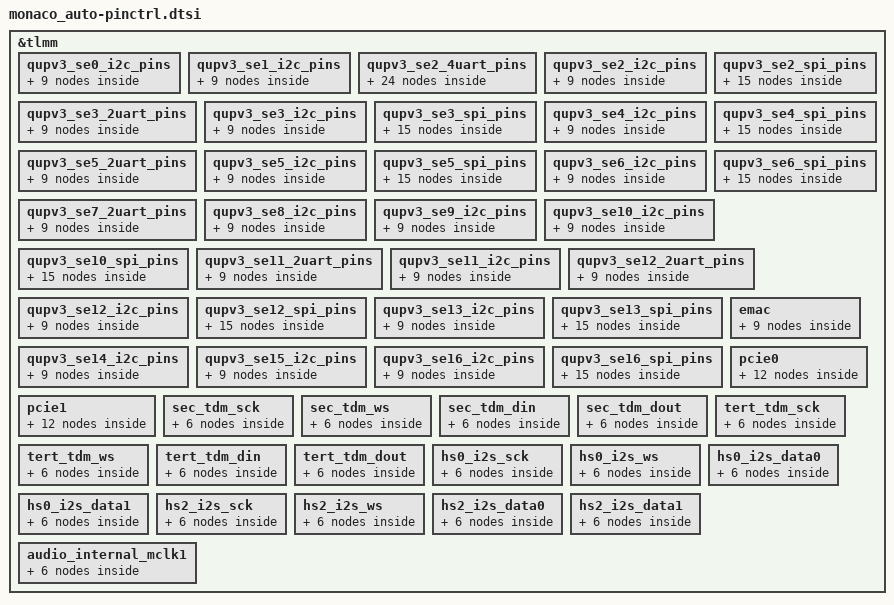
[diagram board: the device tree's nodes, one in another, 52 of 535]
&tlmm {
	qupv3_se0_i2c_pins: qupv3_se0_i2c_pins {
		qupv3_se0_i2c_sda_active: qupv3_se0_i2c_sda_active {
			mux {
				pins = "gpio17";
				function = "qup0_se0_l0";
			};

			config {
				pins = "gpio17";
				drive-strength = <2>;
				bias-pull-up;
			};
		};

		qupv3_se0_i2c_scl_active: qupv3_se0_i2c_scl_active {
			mux {
				pins = "gpio18";
				function = "qup0_se0_l1";
			};

			config {
				pins = "gpio18";
				drive-strength = <2>;
				bias-pull-up;
			};
		};

		qupv3_se0_i2c_sleep: qupv3_se0_i2c_sleep {
			mux {
				pins = "gpio17", "gpio18";
				function = "gpio";
			};

			config {
				pins = "gpio17", "gpio18";
				drive-strength = <2>;
				bias-disable;
			};
		};
	};

	qupv3_se1_i2c_pins: qupv3_se1_i2c_pins {
		qupv3_se1_i2c_sda_active: qupv3_se1_i2c_sda_active {
			mux {
				pins = "gpio19";
				function = "qup0_se1_l0";
			};

			config {
				pins = "gpio19";
				drive-strength = <2>;
				bias-pull-up;
			};
		};

		qupv3_se1_i2c_scl_active: qupv3_se1_i2c_scl_active {
			mux {
				pins = "gpio20";
				function = "qup0_se1_l1";
			};

			config {
				pins = "gpio20";
				drive-strength = <2>;
				bias-pull-up;
			};
		};

		qupv3_se1_i2c_sleep: qupv3_se1_i2c_sleep {
			mux {
				pins = "gpio19", "gpio20";
				function = "gpio";
			};

			config {
				pins = "gpio19", "gpio20";
				drive-strength = <2>;
				bias-disable;
			};
		};
	};

	qupv3_se2_4uart_pins: qupv3_se2_4uart_pins {
		qupv3_se2_default_cts: qupv3_se2_default_cts {
			mux {
				pins = "gpio33";
				function = "gpio";
			};

			config {
				pins = "gpio33";
				drive-strength = <2>;
				bias-disable;
			};
		};

		qupv3_se2_default_rts: qupv3_se2_default_rts {
			mux {
				pins = "gpio34";
				function = "gpio";
			};

			config {
				pins = "gpio34";
				drive-strength = <2>;
				bias-pull-down;
			};
		};

		qupv3_se2_default_tx: qupv3_se2_default_tx {
			mux {
				pins = "gpio35";
				function = "gpio";
			};

			config {
				pins = "gpio35";
				drive-strength = <2>;
				bias-pull-up;
			};
		};

		qupv3_se2_default_rx: qupv3_se2_default_rx {
			mux {
				pins = "gpio36";
				function = "gpio";
			};

			config {
				pins = "gpio36";
				drive-strength = <2>;
				bias-pull-down;
			};
		};

		qupv3_se2_cts: qupv3_se2_cts {
			mux {
				pins = "gpio33";
				function = "qup0_se2_l0";
			};

			config {
				pins = "gpio33";
				drive-strength = <2>;
				bias-disable;
			};
		};

		qupv3_se2_rts: qupv3_se2_rts {
			mux {
				pins = "gpio34";
				function = "qup0_se2_l1";
			};

			config {
				pins = "gpio34";
				drive-strength = <2>;
				bias-pull-down;
			};
		};

		qupv3_se2_tx: qupv3_se2_tx {
			mux {
				pins = "gpio35";
				function = "qup0_se2_l2";
			};

			config {
				pins = "gpio35";
				drive-strength = <2>;
				bias-pull-up;
			};
		};

		qupv3_se2_rx: qupv3_se2_rx {
			mux {
				pins = "gpio36";
				function = "qup0_se2_l3";
			};

			config {
				pins = "gpio36";
				drive-strength = <2>;
				bias-disable;
			};
		};
	};

	qupv3_se2_i2c_pins: qupv3_se2_i2c_pins {
		qupv3_se2_i2c_sda_active: qupv3_se2_i2c_sda_active {
			mux {
				pins = "gpio33";
				function = "qup0_se2_l0";
			};

			config {
				pins = "gpio33";
				drive-strength = <2>;
				bias-pull-up;
			};
		};

		qupv3_se2_i2c_scl_active: qupv3_se2_i2c_scl_active {
			mux {
				pins = "gpio34";
				function = "qup0_se2_l1";
			};

			config {
				pins = "gpio34";
				drive-strength = <2>;
				bias-pull-up;
			};
		};

		qupv3_se2_i2c_sleep: qupv3_se2_i2c_sleep {
			mux {
				pins = "gpio33", "gpio34";
				function = "gpio";
			};

			config {
				pins = "gpio33", "gpio34";
				drive-strength = <2>;
				bias-disable;
			};
		};
	};

	qupv3_se2_spi_pins: qupv3_se2_spi_pins {
		qupv3_se2_spi_miso_active: qupv3_se2_spi_miso_active {
			mux {
				pins = "gpio33";
				function = "qup0_se2_l0";
			};

			config {
				pins = "gpio33";
				drive-strength = <6>;
				bias-disable;
			};
		};

		qupv3_se2_spi_mosi_active: qupv3_se2_spi_mosi_active {
			mux {
				pins = "gpio34";
				function = "qup0_se2_l1";
			};

			config {
				pins = "gpio34";
				drive-strength = <6>;
				bias-disable;
			};
		};

		qupv3_se2_spi_clk_active: qupv3_se2_spi_clk_active {
			mux {
				pins = "gpio35";
				function = "qup0_se2_l2";
			};

			config {
				pins = "gpio35";
				drive-strength = <6>;
				bias-disable;
			};
		};

		qupv3_se2_spi_cs_active: qupv3_se2_spi_cs_active {
			mux {
				pins = "gpio36";
				function = "qup0_se2_l3";
			};

			config {
				pins = "gpio36";
				drive-strength = <6>;
				bias-disable;
			};
		};

		qupv3_se2_spi_sleep: qupv3_se2_spi_sleep {
			mux {
				pins = "gpio33", "gpio34",
					"gpio35", "gpio36";
				function = "gpio";
			};

			config {
				pins = "gpio33", "gpio34",
					"gpio35", "gpio36";
				drive-strength = <2>;
				bias-disable;
			};
		};
	};

	qupv3_se3_2uart_pins: qupv3_se3_2uart_pins {
		qupv3_se3_2uart_tx_active: qupv3_se3_2uart_tx_active {
			mux {
				pins = "gpio27";
				function = "qup0_se3_l2";
			};

			config {
				pins = "gpio27";
				drive-strength = <2>;
				bias-disable;
			};
		};

		qupv3_se3_2uart_rx_active: qupv3_se3_2uart_rx_active {
			mux {
				pins = "gpio28";
				function = "qup0_se3_l3";
			};

			config {
				pins = "gpio28";
				drive-strength = <2>;
				bias-disable;
			};
		};

		qupv3_se3_2uart_sleep: qupv3_se3_2uart_sleep {
			mux {
				pins = "gpio27", "gpio28";
				function = "gpio";
			};

			config {
				pins = "gpio27", "gpio28";
				drive-strength = <2>;
				bias-pull-down;
			};
		};
	};

	qupv3_se3_i2c_pins: qupv3_se3_i2c_pins {
		qupv3_se3_i2c_sda_active: qupv3_se3_i2c_sda_active {
			mux {
				pins = "gpio25";
				function = "qup0_se3_l0";
			};

			config {
				pins = "gpio25";
				drive-strength = <2>;
				bias-pull-up;
			};
		};

		qupv3_se3_i2c_scl_active: qupv3_se3_i2c_scl_active {
			mux {
				pins = "gpio26";
				function = "qup0_se3_l1";
			};

			config {
				pins = "gpio26";
				drive-strength = <2>;
				bias-pull-up;
			};
		};

		qupv3_se3_i2c_sleep: qupv3_se3_i2c_sleep {
			mux {
				pins = "gpio25", "gpio26";
				function = "gpio";
			};

			config {
				pins = "gpio25", "gpio26";
				drive-strength = <2>;
				bias-disable;
			};
		};
	};

	qupv3_se3_spi_pins: qupv3_se3_spi_pins {
		qupv3_se3_spi_miso_active: qupv3_se3_spi_miso_active {
			mux {
				pins = "gpio25";
				function = "qup0_se3_l0";
			};

			config {
				pins = "gpio25";
				drive-strength = <6>;
				bias-disable;
			};
		};

		qupv3_se3_spi_mosi_active: qupv3_se3_spi_mosi_active {
			mux {
				pins = "gpio26";
				function = "qup0_se3_l1";
			};

			config {
				pins = "gpio26";
				drive-strength = <6>;
				bias-disable;
			};
		};

		qupv3_se3_spi_clk_active: qupv3_se3_spi_clk_active {
			mux {
				pins = "gpio27";
				function = "qup0_se3_l2";
			};

			config {
				pins = "gpio27";
				drive-strength = <6>;
				bias-disable;
			};
		};

		qupv3_se3_spi_cs_active: qupv3_se3_spi_cs_active {
			mux {
				pins = "gpio28";
				function = "qup0_se3_l3";
			};

			config {
				pins = "gpio28";
				drive-strength = <6>;
				bias-disable;
			};
		};

		qupv3_se3_spi_sleep: qupv3_se3_spi_sleep {
			mux {
				pins = "gpio25", "gpio26",
					"gpio27", "gpio28";
				function = "gpio";
			};

			config {
				pins = "gpio25", "gpio26",
					"gpio27", "gpio28";
				drive-strength = <2>;
				bias-disable;
			};
		};
	};

	qupv3_se4_i2c_pins: qupv3_se4_i2c_pins {
		qupv3_se4_i2c_sda_active: qupv3_se4_i2c_sda_active {
			mux {
				pins = "gpio29";
				function = "qup0_se4_l0";
			};

			config {
				pins = "gpio29";
				drive-strength = <2>;
				bias-pull-up;
			};
		};

		qupv3_se4_i2c_scl_active: qupv3_se4_i2c_scl_active {
			mux {
				pins = "gpio30";
				function = "qup0_se4_l1";
			};

			config {
				pins = "gpio30";
				drive-strength = <2>;
				bias-pull-up;
			};
		};

		qupv3_se4_i2c_sleep: qupv3_se4_i2c_sleep {
			mux {
				pins = "gpio29", "gpio30";
				function = "gpio";
			};

			config {
				pins = "gpio29", "gpio30";
				drive-strength = <2>;
				bias-disable;
			};
		};
	};

	qupv3_se4_spi_pins: qupv3_se4_spi_pins {
		qupv3_se4_spi_miso_active: qupv3_se4_spi_miso_active {
			mux {
				pins = "gpio29";
				function = "qup0_se4_l0";
			};

			config {
				pins = "gpio29";
				drive-strength = <6>;
				bias-disable;
			};
		};

		qupv3_se4_spi_mosi_active: qupv3_se4_spi_mosi_active {
			mux {
				pins = "gpio30";
				function = "qup0_se4_l1";
			};

			config {
				pins = "gpio30";
				drive-strength = <6>;
				bias-disable;
			};
		};

		qupv3_se4_spi_clk_active: qupv3_se4_spi_clk_active {
			mux {
				pins = "gpio31";
				function = "qup0_se4_l2";
			};

			config {
				pins = "gpio31";
				drive-strength = <6>;
				bias-disable;
			};
		};

		qupv3_se4_spi_cs_active: qupv3_se4_spi_cs_active {
			mux {
				pins = "gpio32";
				function = "qup0_se4_l3";
			};

			config {
				pins = "gpio32";
				drive-strength = <6>;
				bias-disable;
			};
		};

		qupv3_se4_spi_sleep: qupv3_se4_spi_sleep {
			mux {
				pins = "gpio29", "gpio30",
					"gpio31", "gpio32";
				function = "gpio";
			};

			config {
				pins = "gpio29", "gpio30",
					"gpio31", "gpio32";
				drive-strength = <2>;
				bias-disable;
			};
		};
	};

	qupv3_se5_2uart_pins: qupv3_se5_2uart_pins {
		qupv3_se5_2uart_tx_active: qupv3_se5_2uart_tx_active {
			mux {
				pins = "gpio23";
				function = "qup0_se5_l2";
			};

			config {
				pins = "gpio23";
				drive-strength = <2>;
				bias-disable;
			};
		};

		qupv3_se5_2uart_rx_active: qupv3_se5_2uart_rx_active {
			mux {
				pins = "gpio24";
				function = "qup0_se5_l3";
			};

			config {
				pins = "gpio24";
				drive-strength = <2>;
				bias-disable;
			};
		};

		qupv3_se5_2uart_sleep: qupv3_se5_2uart_sleep {
			mux {
				pins = "gpio23", "gpio24";
				function = "gpio";
			};

			config {
				pins = "gpio23", "gpio24";
				drive-strength = <2>;
				bias-pull-down;
			};
		};
	};

	qupv3_se5_i2c_pins: qupv3_se5_i2c_pins {
		qupv3_se5_i2c_sda_active: qupv3_se5_i2c_sda_active {
			mux {
				pins = "gpio21";
				function = "qup0_se5_l0";
			};

			config {
				pins = "gpio21";
				drive-strength = <2>;
				bias-pull-up;
			};
		};

		qupv3_se5_i2c_scl_active: qupv3_se5_i2c_scl_active {
			mux {
				pins = "gpio22";
				function = "qup0_se5_l1";
			};

			config {
				pins = "gpio22";
				drive-strength = <2>;
				bias-pull-up;
			};
		};

		qupv3_se5_i2c_sleep: qupv3_se5_i2c_sleep {
			mux {
				pins = "gpio21", "gpio22";
				function = "gpio";
			};

			config {
				pins = "gpio21", "gpio22";
				drive-strength = <2>;
				bias-disable;
			};
		};
	};

	qupv3_se5_spi_pins: qupv3_se5_spi_pins {
		qupv3_se5_spi_miso_active: qupv3_se5_spi_miso_active {
			mux {
				pins = "gpio21";
				function = "qup0_se5_l0";
			};

			config {
				pins = "gpio21";
				drive-strength = <6>;
				bias-disable;
			};
		};

		qupv3_se5_spi_mosi_active: qupv3_se5_spi_mosi_active {
			mux {
				pins = "gpio22";
				function = "qup0_se5_l1";
			};

			config {
				pins = "gpio22";
				drive-strength = <6>;
				bias-disable;
			};
		};

		qupv3_se5_spi_clk_active: qupv3_se5_spi_clk_active {
			mux {
				pins = "gpio23";
				function = "qup0_se5_l2";
			};

			config {
				pins = "gpio23";
				drive-strength = <6>;
				bias-disable;
			};
		};

		qupv3_se5_spi_cs_active: qupv3_se5_spi_cs_active {
			mux {
				pins = "gpio24";
				function = "qup0_se5_l3";
			};

			config {
				pins = "gpio24";
				drive-strength = <6>;
				bias-disable;
			};
		};

		qupv3_se5_spi_sleep: qupv3_se5_spi_sleep {
			mux {
				pins = "gpio21", "gpio22",
					"gpio23", "gpio24";
				function = "gpio";
			};

			config {
				pins = "gpio21", "gpio22",
					"gpio23", "gpio24";
				drive-strength = <2>;
				bias-disable;
			};
		};
	};

	qupv3_se6_i2c_pins: qupv3_se6_i2c_pins {
		qupv3_se6_i2c_sda_active: qupv3_se6_i2c_sda_active {
			mux {
				pins = "gpio80";
				function = "qup0_se6_l0";
			};

			config {
				pins = "gpio80";
				drive-strength = <2>;
				bias-pull-up;
			};
		};

		qupv3_se6_i2c_scl_active: qupv3_se6_i2c_scl_active {
			mux {
				pins = "gpio81";
				function = "qup0_se6_l1";
			};

			config {
				pins = "gpio81";
				drive-strength = <2>;
				bias-pull-up;
			};
		};

		qupv3_se6_i2c_sleep: qupv3_se6_i2c_sleep {
			mux {
				pins = "gpio80", "gpio81";
				function = "gpio";
			};

			config {
				pins = "gpio80", "gpio81";
				drive-strength = <2>;
				bias-disable;
			};
		};
	};

	qupv3_se6_spi_pins: qupv3_se6_spi_pins {
		qupv3_se6_spi_miso_active: qupv3_se6_spi_miso_active {
			mux {
				pins = "gpio80";
				function = "qup0_se6_l0";
			};

			config {
				pins = "gpio80";
				drive-strength = <6>;
				bias-disable;
			};
		};

		qupv3_se6_spi_mosi_active: qupv3_se6_spi_mosi_active {
			mux {
				pins = "gpio81";
				function = "qup0_se6_l1";
			};

			config {
				pins = "gpio81";
				drive-strength = <6>;
				bias-disable;
			};
		};

		qupv3_se6_spi_clk_active: qupv3_se6_spi_clk_active {
			mux {
				pins = "gpio82";
				function = "qup0_se6_l2";
			};

			config {
				pins = "gpio82";
				drive-strength = <6>;
				bias-disable;
			};
		};

		qupv3_se6_spi_cs_active: qupv3_se6_spi_cs_active {
			mux {
				pins = "gpio83";
				function = "qup0_se6_l3";
			};

			config {
				pins = "gpio83";
				drive-strength = <6>;
				bias-disable;
			};
		};

		qupv3_se6_spi_sleep: qupv3_se6_spi_sleep {
			mux {
				pins = "gpio80", "gpio81",
					"gpio82", "gpio83";
				function = "gpio";
			};

			config {
				pins = "gpio80", "gpio81",
					"gpio82", "gpio83";
				drive-strength = <2>;
				bias-disable;
			};
		};
	};

	qupv3_se7_2uart_pins: qupv3_se7_2uart_pins {
		qupv3_se7_2uart_tx_active: qupv3_se7_2uart_tx_active {
			mux {
				pins = "gpio43";
				function = "qup0_se7_l2";
			};

			config {
				pins = "gpio43";
				drive-strength = <2>;
				bias-disable;
			};
		};

		qupv3_se7_2uart_rx_active: qupv3_se7_2uart_rx_active {
			mux {
				pins = "gpio44";
				function = "qup0_se7_l3";
			};

			config {
				pins = "gpio44";
				drive-strength = <2>;
				bias-disable;
			};
		};

		qupv3_se7_2uart_sleep: qupv3_se7_2uart_sleep {
			mux {
				pins = "gpio43", "gpio44";
				function = "gpio";
			};

			config {
				pins = "gpio43", "gpio44";
				drive-strength = <2>;
				bias-pull-down;
			};
		};
	};

	qupv3_se8_i2c_pins: qupv3_se8_i2c_pins {
		qupv3_se8_i2c_sda_active: qupv3_se8_i2c_sda_active {
			mux {
				pins = "gpio37";
				function = "qup1_se0_l0";
			};

			config {
				pins = "gpio37";
				drive-strength = <2>;
				bias-pull-up;
			};
		};

		qupv3_se8_i2c_scl_active: qupv3_se8_i2c_scl_active {
			mux {
				pins = "gpio38";
				function = "qup1_se0_l1";
			};

			config {
				pins = "gpio38";
				drive-strength = <2>;
				bias-pull-up;
			};
		};

		qupv3_se8_i2c_sleep: qupv3_se8_i2c_sleep {
			mux {
				pins = "gpio37", "gpio38";
				function = "gpio";
			};

			config {
				pins = "gpio37", "gpio38";
				drive-strength = <2>;
				bias-disable;
			};
		};
	};

	qupv3_se9_i2c_pins: qupv3_se9_i2c_pins {
		qupv3_se9_i2c_sda_active: qupv3_se9_i2c_sda_active {
			mux {
				pins = "gpio39";
				function = "qup1_se1_l0";
			};

			config {
				pins = "gpio39";
				drive-strength = <2>;
				bias-pull-up;
			};
		};

		qupv3_se9_i2c_scl_active: qupv3_se9_i2c_scl_active {
			mux {
				pins = "gpio40";
				function = "qup1_se1_l1";
			};

			config {
				pins = "gpio40";
				drive-strength = <2>;
				bias-pull-up;
			};
		};

		qupv3_se9_i2c_sleep: qupv3_se9_i2c_sleep {
			mux {
				pins = "gpio39", "gpio40";
				function = "gpio";
			};

			config {
				pins = "gpio39", "gpio40";
				drive-strength = <2>;
				bias-disable;
			};
		};
	};

	qupv3_se10_i2c_pins: qupv3_se10_i2c_pins {
		qupv3_se10_i2c_sda_active: qupv3_se10_i2c_sda_active {
			mux {
				pins = "gpio84";
				function = "qup1_se2_l0";
			};

			config {
				pins = "gpio84";
				drive-strength = <2>;
				bias-pull-up;
			};
		};

		qupv3_se10_i2c_scl_active: qupv3_se10_i2c_scl_active {
			mux {
				pins = "gpio85";
				function = "qup1_se2_l1";
			};

			config {
				pins = "gpio85";
				drive-strength = <2>;
				bias-pull-up;
			};
		};

		qupv3_se10_i2c_sleep: qupv3_se10_i2c_sleep {
			mux {
				pins = "gpio84", "gpio85";
				function = "gpio";
			};

			config {
				pins = "gpio84", "gpio85";
				drive-strength = <2>;
				bias-disable;
			};
		};
	};

	qupv3_se10_spi_pins: qupv3_se10_spi_pins {
		qupv3_se10_spi_miso_active: qupv3_se10_spi_miso_active {
			mux {
				pins = "gpio84";
				function = "qup1_se2_l0";
			};

			config {
				pins = "gpio84";
				drive-strength = <6>;
				bias-disable;
			};
		};

		qupv3_se10_spi_mosi_active: qupv3_se10_spi_mosi_active {
			mux {
				pins = "gpio85";
				function = "qup1_se2_l1";
			};

			config {
				pins = "gpio85";
				drive-strength = <6>;
				bias-disable;
			};
		};

		qupv3_se10_spi_clk_active: qupv3_se10_spi_clk_active {
			mux {
				pins = "gpio86";
				function = "qup1_se2_l2";
			};

			config {
				pins = "gpio86";
				drive-strength = <6>;
				bias-disable;
			};
		};

		qupv3_se10_spi_cs_active: qupv3_se10_spi_cs_active {
			mux {
				pins = "gpio87";
				function = "qup1_se2_l3";
			};

			config {
				pins = "gpio87";
				drive-strength = <6>;
				bias-disable;
			};
		};

		qupv3_se10_spi_sleep: qupv3_se10_spi_sleep {
			mux {
				pins = "gpio84", "gpio85",
					"gpio86", "gpio87";
				function = "gpio";
			};

			config {
				pins = "gpio84", "gpio85",
					"gpio86", "gpio87";
				drive-strength = <2>;
				bias-disable;
			};
		};
	};

	qupv3_se11_2uart_pins: qupv3_se11_2uart_pins {
		qupv3_se11_2uart_tx_active: qupv3_se11_2uart_tx_active {
			mux {
				pins = "gpio41";
				function = "qup1_se3_l2";
			};

			config {
				pins = "gpio41";
				drive-strength = <2>;
				bias-disable;
			};
		};

		qupv3_se11_2uart_rx_active: qupv3_se11_2uart_rx_active {
			mux {
				pins = "gpio42";
				function = "qup1_se3_l3";
			};

			config {
				pins = "gpio42";
				drive-strength = <2>;
				bias-disable;
			};
		};

		qupv3_se11_2uart_sleep: qupv3_se11_2uart_sleep {
			mux {
				pins = "gpio41", "gpio42";
				function = "gpio";
			};

			config {
				pins = "gpio41", "gpio42";
				drive-strength = <2>;
				bias-pull-down;
			};
		};
	};

	qupv3_se11_i2c_pins: qupv3_se11_i2c_pins {
		qupv3_se11_i2c_sda_active: qupv3_se11_i2c_sda_active {
			mux {
				pins = "gpio41";
				function = "qup1_se3_l0";
			};

			config {
				pins = "gpio41";
				drive-strength = <2>;
				bias-pull-up;
			};
		};

		qupv3_se11_i2c_scl_active: qupv3_se11_i2c_scl_active {
			mux {
				pins = "gpio42";
				function = "qup1_se3_l1";
			};

			config {
				pins = "gpio42";
				drive-strength = <2>;
				bias-pull-up;
			};
		};

		qupv3_se11_i2c_sleep: qupv3_se11_i2c_sleep {
			mux {
				pins = "gpio41", "gpio42";
				function = "gpio";
			};

			config {
				pins = "gpio41", "gpio42";
				drive-strength = <2>;
				bias-disable;
			};
		};
	};

	qupv3_se12_2uart_pins: qupv3_se12_2uart_pins {
		qupv3_se12_2uart_tx_active: qupv3_se12_2uart_tx_active {
			mux {
				pins = "gpio47";
				function = "qup1_se4_l2";
			};

			config {
				pins = "gpio47";
				drive-strength = <2>;
				bias-disable;
			};
		};

		qupv3_se12_2uart_rx_active: qupv3_se12_2uart_rx_active {
			mux {
				pins = "gpio48";
				function = "qup1_se4_l3";
			};

			config {
				pins = "gpio48";
				drive-strength = <2>;
				bias-disable;
			};
		};

		qupv3_se12_2uart_sleep: qupv3_se12_2uart_sleep {
			mux {
				pins = "gpio47", "gpio48";
				function = "gpio";
			};

			config {
				pins = "gpio47", "gpio48";
				drive-strength = <2>;
				bias-pull-down;
			};
		};
	};

	qupv3_se12_i2c_pins: qupv3_se12_i2c_pins {
		qupv3_se12_i2c_sda_active: qupv3_se12_i2c_sda_active {
			mux {
				pins = "gpio45";
				function = "qup1_se4_l0";
			};

			config {
				pins = "gpio45";
				drive-strength = <2>;
				bias-pull-up;
			};
		};

		qupv3_se12_i2c_scl_active: qupv3_se12_i2c_scl_active {
			mux {
				pins = "gpio46";
				function = "qup1_se4_l1";
			};

			config {
				pins = "gpio46";
				drive-strength = <2>;
				bias-pull-up;
			};
		};

		qupv3_se12_i2c_sleep: qupv3_se12_i2c_sleep {
			mux {
				pins = "gpio45", "gpio46";
				function = "gpio";
			};

			config {
				pins = "gpio45", "gpio46";
				drive-strength = <2>;
				bias-disable;
			};
		};
	};

	qupv3_se12_spi_pins: qupv3_se12_spi_pins {
		qupv3_se12_spi_miso_active: qupv3_se12_spi_miso_active {
			mux {
				pins = "gpio45";
				function = "qup1_se4_l0";
			};

			config {
				pins = "gpio45";
				drive-strength = <6>;
				bias-disable;
			};
		};

		qupv3_se12_spi_mosi_active: qupv3_se12_spi_mosi_active {
			mux {
				pins = "gpio46";
				function = "qup1_se4_l1";
			};

			config {
				pins = "gpio46";
				drive-strength = <6>;
				bias-disable;
			};
		};

		qupv3_se12_spi_clk_active: qupv3_se12_spi_clk_active {
			mux {
				pins = "gpio47";
				function = "qup1_se4_l2";
			};

			config {
				pins = "gpio47";
				drive-strength = <6>;
				bias-disable;
			};
		};

		qupv3_se12_spi_cs_active: qupv3_se12_spi_cs_active {
			mux {
				pins = "gpio48";
				function = "qup1_se4_l3";
			};

			config {
				pins = "gpio48";
				drive-strength = <6>;
				bias-disable;
			};
		};

		qupv3_se12_spi_sleep: qupv3_se12_spi_sleep {
			mux {
				pins = "gpio45", "gpio46",
					"gpio47", "gpio48";
				function = "gpio";
			};

			config {
				pins = "gpio45", "gpio46",
					"gpio47", "gpio48";
				drive-strength = <2>;
				bias-disable;
			};
		};
	};

	qupv3_se13_i2c_pins: qupv3_se13_i2c_pins {
		qupv3_se13_i2c_sda_active: qupv3_se13_i2c_sda_active {
			mux {
				pins = "gpio49";
				function = "qup1_se5_l0";
			};

			config {
				pins = "gpio49";
				drive-strength = <2>;
				bias-pull-up;
			};
		};

		qupv3_se13_i2c_scl_active: qupv3_se13_i2c_scl_active {
			mux {
				pins = "gpio50";
				function = "qup1_se5_l1";
			};

			config {
				pins = "gpio50";
				drive-strength = <2>;
				bias-pull-up;
			};
		};

		qupv3_se13_i2c_sleep: qupv3_se13_i2c_sleep {
			mux {
				pins = "gpio49", "gpio50";
				function = "gpio";
			};

			config {
				pins = "gpio49", "gpio50";
				drive-strength = <2>;
				bias-disable;
			};
		};
	};

	qupv3_se13_spi_pins: qupv3_se13_spi_pins {
		qupv3_se13_spi_miso_active: qupv3_se13_spi_miso_active {
			mux {
				pins = "gpio49";
				function = "qup1_se5_l0";
			};

			config {
				pins = "gpio49";
				drive-strength = <6>;
				bias-disable;
			};
		};

		qupv3_se13_spi_mosi_active: qupv3_se13_spi_mosi_active {
			mux {
				pins = "gpio50";
				function = "qup1_se5_l1";
			};

			config {
				pins = "gpio50";
				drive-strength = <6>;
				bias-disable;
			};
		};

		qupv3_se13_spi_clk_active: qupv3_se13_spi_clk_active {
			mux {
				pins = "gpio51";
				function = "qup1_se5_l2";
			};

			config {
				pins = "gpio51";
				drive-strength = <6>;
				bias-disable;
			};
		};

		qupv3_se13_spi_cs_active: qupv3_se13_spi_cs_active {
			mux {
				pins = "gpio52";
				function = "qup1_se5_l3";
			};

			config {
				pins = "gpio52";
				drive-strength = <6>;
				bias-disable;
			};
		};

		qupv3_se13_spi_sleep: qupv3_se13_spi_sleep {
			mux {
				pins = "gpio49", "gpio50",
					"gpio51", "gpio52";
				function = "gpio";
			};

			config {
				pins = "gpio49", "gpio50",
					"gpio51", "gpio52";
				drive-strength = <2>;
				bias-disable;
			};
		};
	};

	qupv3_se14_i2c_pins: qupv3_se14_i2c_pins {
		qupv3_se14_i2c_sda_active: qupv3_se14_i2c_sda_active {
			mux {
				pins = "gpio89";
				function = "qup1_se6_l0";
			};

			config {
				pins = "gpio89";
				drive-strength = <2>;
				bias-pull-up;
			};
		};

		qupv3_se14_i2c_scl_active: qupv3_se14_i2c_scl_active {
			mux {
				pins = "gpio90";
				function = "qup1_se6_l1";
			};

			config {
				pins = "gpio90";
				drive-strength = <2>;
				bias-pull-up;
			};
		};

		qupv3_se14_i2c_sleep: qupv3_se14_i2c_sleep {
			mux {
				pins = "gpio89", "gpio90";
				function = "gpio";
			};

			config {
				pins = "gpio89", "gpio90";
				drive-strength = <2>;
				bias-disable;
			};
		};
	};

	qupv3_se15_i2c_pins: qupv3_se15_i2c_pins {
		qupv3_se15_i2c_sda_active: qupv3_se15_i2c_sda_active {
			mux {
				pins = "gpio91";
				function = "qup1_se7_l0";
			};

			config {
				pins = "gpio91";
				drive-strength = <2>;
				bias-pull-up;
			};
		};

		qupv3_se15_i2c_scl_active: qupv3_se15_i2c_scl_active {
			mux {
				pins = "gpio92";
				function = "qup1_se7_l1";
			};

			config {
				pins = "gpio92";
				drive-strength = <2>;
				bias-pull-up;
			};
		};

		qupv3_se15_i2c_sleep: qupv3_se15_i2c_sleep {
			mux {
				pins = "gpio91", "gpio92";
				function = "gpio";
			};

			config {
				pins = "gpio91", "gpio92";
				drive-strength = <2>;
				bias-disable;
			};
		};
	};

	qupv3_se16_i2c_pins: qupv3_se16_i2c_pins {
		qupv3_se16_i2c_sda_active: qupv3_se16_i2c_sda_active {
			mux {
				pins = "gpio10";
				function = "qup3_se0_l0";
			};

			config {
				pins = "gpio10";
				drive-strength = <2>;
				bias-pull-up;
			};
		};

		qupv3_se16_i2c_scl_active: qupv3_se16_i2c_scl_active {
			mux {
				pins = "gpio11";
				function = "qup3_se0_l1";
			};

			config {
				pins = "gpio11";
				drive-strength = <2>;
				bias-pull-up;
			};
		};

		qupv3_se16_i2c_sleep: qupv3_se16_i2c_sleep {
			mux {
				pins = "gpio10", "gpio11";
				function = "gpio";
			};

			config {
				pins = "gpio10", "gpio11";
				drive-strength = <2>;
				bias-disable;
			};
		};
	};

	qupv3_se16_spi_pins: qupv3_se16_spi_pins {
		qupv3_se16_spi_miso_active: qupv3_se16_spi_miso_active {
			mux {
				pins = "gpio10";
				function = "qup3_se0_l0";
			};

			config {
				pins = "gpio10";
				drive-strength = <6>;
				bias-disable;
			};
		};

		qupv3_se16_spi_mosi_active: qupv3_se16_spi_mosi_active {
			mux {
				pins = "gpio11";
				function = "qup3_se0_l1";
			};

			config {
				pins = "gpio11";
				drive-strength = <6>;
				bias-disable;
			};
		};

		qupv3_se16_spi_clk_active: qupv3_se16_spi_clk_active {
			mux {
				pins = "gpio12";
				function = "qup3_se0_l2";
			};

			config {
				pins = "gpio12";
				drive-strength = <6>;
				bias-disable;
			};
		};

		qupv3_se16_spi_cs_active: qupv3_se16_spi_cs_active {
			mux {
				pins = "gpio13";
				function = "qup3_se0_l3";
			};

			config {
				pins = "gpio13";
				drive-strength = <6>;
				bias-disable;
			};
		};

		qupv3_se16_spi_sleep: qupv3_se16_spi_sleep {
			mux {
				pins = "gpio10", "gpio11",
					"gpio12", "gpio13";
				function = "gpio";
			};

			config {
				pins = "gpio10", "gpio11",
					"gpio12", "gpio13";
				drive-strength = <2>;
				bias-disable;
			};
		};
	};

	emac {
		emac_mdc: emac_mdc {
			mux {
				pins = "gpio5";
				function = "emac0_mdc";
			};

			config {
				pins = "gpio5";
				bias-pull-up;
				drive-strength = <16>;
			};
		};

		emac_mdio: emac_mdio {
			mux {
					pins = "gpio6";
					function = "emac0_mdio";
			};

			config {
				pins = "gpio6";
				bias-pull-up;
				drive-strength = <16>;
			};
		};

		emac_phy_reset_state: emac_phy_reset_state {
			mux {
				pins = "gpio31";
				function = "gpio";
			};

			config {
				pins = "gpio31";
				bias-pull-up;
				drive-strength = <16>;
			};
		};
	};

	pcie0 {
		pcie0_perst_default: pcie0_perst_default {
			mux {
				pins = "gpio2";
				function = "gpio";
			};

			config {
				pins = "gpio2";
				drive-strength = <2>;
				bias-pull-down;
			};
		};

		pcie0_clkreq_default: pcie0_clkreq_default {
			mux {
				pins = "gpio1";
				function = "pcie0_clkreq_n";
			};

			config {
				pins = "gpio1";
				drive-strength = <2>;
				bias-pull-up;
			};
		};

		pcie0_wake_default: pcie0_wake_default {
			mux {
				pins = "gpio0";
				function = "gpio";
			};

			config {
				pins = "gpio0";
				drive-strength = <2>;
				bias-pull-up;
			};
		};

		pcie0_clkreq_sleep: pcie0_clkreq_sleep {
			mux {
				pins = "gpio1";
				function = "gpio";
			};

			config {
				pins = "gpio1";
				drive-strength = <2>;
				bias-pull-up;
			};
		};
	};

	pcie1 {
		pcie1_perst_default: pcie1_perst_default {
			mux {
				pins = "gpio23";
				function = "gpio";
			};

			config {
				pins = "gpio23";
				drive-strength = <10>;
				bias-disable;
			};
		};

		pcie1_clkreq_default: pcie1_clkreq_default {
			mux {
				pins = "gpio22";
				function = "pcie1_clkreq_n";
			};

			config {
				pins = "gpio22";
				drive-strength = <2>;
				bias-pull-up;
			};
		};

		pcie1_wake_default: pcie1_wake_default {
			mux {
				pins = "gpio21";
				function = "gpio";
			};

			config {
				pins = "gpio21";
				drive-strength = <2>;
				bias-pull-up;
			};
		};

		pcie1_clkreq_sleep: pcie1_clkreq_sleep {
			mux {
				pins = "gpio22";
				function = "gpio";
			};

			config {
				pins = "gpio22";
				drive-strength = <2>;
				bias-pull-up;
			};
		};
	};

	sec_tdm_sck {
		sec_tdm_sck_sleep: sec_tdm_sck_sleep {
			mux {
				pins = "gpio98";
				function = "gpio";
			};

			config {
				pins = "gpio98";
				drive-strength = <2>;   /* 2 mA */
				bias-pull-down;         /* PULL DOWN */
				input-enable;
			};
		};

		sec_tdm_sck_active: sec_tdm_sck_active {
			mux {
				pins = "gpio98";
				function = "mi2s1_sck";
			};

			config {
				pins = "gpio98";
				drive-strength = <8>;   /* 8 mA */
				bias-disable;           /* NO PULL */
				output-high;
			};
		};
	};

	sec_tdm_ws {
		sec_tdm_ws_sleep: sec_tdm_ws_sleep {
			mux {
				pins = "gpio99";
				function = "gpio";
			};

			config {
				pins = "gpio99";
				drive-strength = <2>;   /* 2 mA */
				bias-pull-down;         /* PULL DOWN */
				input-enable;
			};
		};

		sec_tdm_ws_active: sec_tdm_ws_active {
			mux {
				pins = "gpio99";
				function = "mi2s1_ws";
			};

			config {
				pins = "gpio99";
				drive-strength = <8>;   /* 8 mA */
				bias-disable;           /* NO PULL */
				output-high;
			};
		};
	};

	sec_tdm_din {
		sec_tdm_din_sleep: sec_tdm_din_sleep {
			mux {
				pins = "gpio100";
				function = "gpio";
			};

			config {
				pins = "gpio100";
				drive-strength = <2>;   /* 2 mA */
				bias-pull-down;         /* PULL DOWN */
				input-enable;
			};
		};

		sec_tdm_din_active: sec_tdm_din_active {
			mux {
				pins = "gpio100";
				function = "mi2s1_data0";
			};

			config {
				pins = "gpio100";
				drive-strength = <8>;   /* 8 mA */
				bias-disable;           /* NO PULL */
			};
		};
	};

	sec_tdm_dout {
		sec_tdm_dout_sleep: sec_tdm_dout_sleep {
			mux {
				pins = "gpio101";
				function = "gpio";
			};

			config {
				pins = "gpio101";
				drive-strength = <2>;   /* 2 mA */
				bias-pull-down;         /* PULL DOWN */
				input-enable;
			};
		};

		sec_tdm_dout_active: sec_tdm_dout_active {
			mux {
				pins = "gpio101";
				function = "mi2s1_data1";
			};

			config {
				pins = "gpio101";
				drive-strength = <8>;   /* 8 mA */
				bias-disable;           /* NO PULL */
				output-high;
			};
		};
	};

	tert_tdm_sck {
		tert_tdm_sck_sleep: tert_tdm_sck_sleep {
			mux {
				pins = "gpio102";
				function = "gpio";
			};

			config {
				pins = "gpio102";
				drive-strength = <2>;   /* 2 mA */
				bias-pull-down;         /* PULL DOWN */
				input-enable;
			};
		};

		tert_tdm_sck_active: tert_tdm_sck_active {
			mux {
				pins = "gpio102";
				function = "mi2s2_sck";
			};

			config {
				pins = "gpio102";
				drive-strength = <8>;   /* 8 mA */
				bias-disable;           /* NO PULL */
				output-high;
			};
		};
	};

	tert_tdm_ws {
		tert_tdm_ws_sleep: tert_tdm_ws_sleep {
			mux {
				pins = "gpio103";
				function = "gpio";
			};

			config {
				pins = "gpio103";
				drive-strength = <2>;   /* 2 mA */
				bias-pull-down;         /* PULL DOWN */
				input-enable;
			};
		};

		tert_tdm_ws_active: tert_tdm_ws_active {
			mux {
				pins = "gpio103";
				function = "mi2s2_ws";
			};

			config {
				pins = "gpio103";
				drive-strength = <8>;   /* 8 mA */
				bias-disable;           /* NO PULL */
				output-high;
			};
		};
	};

	tert_tdm_din {
		tert_tdm_din_sleep: tert_tdm_din_sleep {
			mux {
				pins = "gpio104";
				function = "gpio";
			};

			config {
				pins = "gpio104";
				drive-strength = <2>;   /* 2 mA */
				bias-pull-down;         /* PULL DOWN */
				input-enable;
			};
		};

		tert_tdm_din_active: tert_tdm_din_active {
			mux {
				pins = "gpio104";
				function = "mi2s2_data0";
			};

			config {
				pins = "gpio104";
				drive-strength = <8>;   /* 8 mA */
				bias-disable;           /* NO PULL */
			};
		};
	};

	tert_tdm_dout {
		tert_tdm_dout_sleep: tert_tdm_dout_sleep {
			mux {
				pins = "gpio105";
				function = "gpio";
			};

			config {
				pins = "gpio105";
				drive-strength = <2>;   /* 2 mA */
				bias-pull-down;         /* PULL DOWN */
				input-enable;
			};
		};

		tert_tdm_dout_active: tert_tdm_dout_active {
			mux {
				pins = "gpio105";
				function = "mi2s2_data1";
			};

			config {
				pins = "gpio105";
				drive-strength = <8>;   /* 8 mA */
				bias-disable;           /* NO PULL */
				output-high;
			};
		};
	};

	hs0_i2s_sck {
		hs0_i2s_sck_sleep: hs0_i2s_sck_sleep {
			mux {
				pins = "gpio106";
				function = "gpio";
			};

			config {
				pins = "gpio106";
				drive-strength = <2>;   /* 2 mA */
				bias-pull-down;         /* PULL DOWN */
				input-enable;
			};
		};

		hs0_i2s_sck_active: hs0_i2s_sck_active {
			mux {
				pins = "gpio106";
				function = "hs0_mi2s_sck";
			};

			config {
				pins = "gpio106";
				drive-strength = <8>;   /* 8 mA */
				bias-disable;           /* NO PULL */
				output-high;
			};
		};
	};

	hs0_i2s_ws {
		hs0_i2s_ws_sleep: hs0_i2s_ws_sleep {
			mux {
				pins = "gpio107";
				function = "gpio";
			};

			config {
				pins = "gpio107";
				drive-strength = <2>;   /* 8 mA */
				bias-pull-down;         /* PULL DOWN */
				input-enable;
			};
		};

		hs0_i2s_ws_active: hs0_i2s_ws_active {
			mux {
				pins = "gpio107";
				function = "hs0_mi2s_ws";
			};

			config {
				pins = "gpio107";
				drive-strength = <8>;   /* 8 mA */
				bias-disable;           /* NO PULL */
				output-high;
			};
		};
	};

	hs0_i2s_data0 {
		hs0_i2s_data0_sleep: hs0_i2s_data0_sleep {
			mux {
				pins = "gpio108";
				function = "gpio";
			};

			config {
				pins = "gpio108";
				drive-strength = <2>;   /* 2 mA */
				bias-pull-down;         /* PULL DOWN */
				input-enable;
			};
		};

		hs0_i2s_data0_active: hs0_i2s_data0_active {
			mux {
				pins = "gpio108";
				function = "hs0_mi2s_data0";
			};

			config {
				pins = "gpio108";
				drive-strength = <8>;   /* 2 mA */
				bias-disable;           /* NO PULL */
			};
		};
	};

	hs0_i2s_data1 {
		hs0_i2s_data1_sleep: hs0_i2s_data1_sleep {
			mux {
				pins = "gpio109";
				function = "gpio";
			};

			config {
				pins = "gpio109";
				drive-strength = <2>;   /* 2 mA */
				bias-pull-down;         /* PULL DOWN */
				input-enable;
			};
		};

		hs0_i2s_data1_active: hs0_i2s_data1_active {
			mux {
				pins = "gpio109";
				function = "hs0_mi2s_data1";
			};

			config {
				pins = "gpio109";
				drive-strength = <8>;   /* 8 mA */
				bias-disable;           /* NO PULL */
				output-high;
			};
		};
	};

	hs2_i2s_sck {
		hs2_i2s_sck_sleep: hs2_i2s_sck_sleep {
			mux {
				pins = "gpio51";
				function = "gpio";
			};

			config {
				pins = "gpio51";
				drive-strength = <2>;   /* 2 mA */
				bias-pull-down;         /* PULL DOWN */
				input-enable;
			};
		};

		hs2_i2s_sck_active: hs2_i2s_sck_active {
			mux {
				pins = "gpio51";
				function = "hs2_mi2s";
			};

			config {
				pins = "gpio51";
				drive-strength = <8>;   /* 8 mA */
				bias-disable;           /* NO PULL */
				output-high;
			};
		};
	};

	hs2_i2s_ws {
		hs2_i2s_ws_sleep: hs2_i2s_ws_sleep {
			mux {
				pins = "gpio52";
				function = "gpio";
			};

			config {
				pins = "gpio52";
				drive-strength = <2>;   /* 8 mA */
				bias-pull-down;         /* PULL DOWN */
				input-enable;
			};
		};

		hs2_i2s_ws_active: hs2_i2s_ws_active {
			mux {
				pins = "gpio52";
				function = "hs2_mi2s";
			};

			config {
				pins = "gpio52";
				drive-strength = <8>;   /* 8 mA */
				bias-disable;           /* NO PULL */
				output-high;
			};
		};
	};

	hs2_i2s_data0 {
		hs2_i2s_data0_sleep: hs2_i2s_data0_sleep {
			mux {
				pins = "gpio49";
				function = "gpio";
			};

			config {
				pins = "gpio49";
				drive-strength = <2>;   /* 2 mA */
				bias-pull-down;         /* PULL DOWN */
				input-enable;
			};
		};

		hs2_i2s_data0_active: hs2_i2s_data0_active {
			mux {
				pins = "gpio49";
				function = "hs2_mi2s";
			};

			config {
				pins = "gpio49";
				drive-strength = <8>;   /* 2 mA */
				bias-disable;           /* NO PULL */
			};
		};
	};

	hs2_i2s_data1 {
		hs2_i2s_data1_sleep: hs2_i2s_data1_sleep {
			mux {
				pins = "gpio50";
				function = "gpio";
			};

			config {
				pins = "gpio50";
				drive-strength = <2>;   /* 2 mA */
				bias-pull-down;         /* PULL DOWN */
				input-enable;
			};
		};

		hs2_i2s_data1_active: hs2_i2s_data1_active {
			mux {
				pins = "gpio50";
				function = "hs2_mi2s";
			};

			config {
				pins = "gpio50";
				drive-strength = <8>;   /* 8 mA */
				bias-disable;           /* NO PULL */
				output-high;
			};
		};
	};

	audio_internal_mclk1 {
		audio_internal_mclk1_sleep: audio_internal_mclk1_sleep {
			mux {
				pins = "gpio97";
				function = "gpio";
			};

			config {
				pins = "gpio97";
				drive-strength = <2>;   /* 2 mA */
				bias-pull-down;         /* PULL DOWN */
			};
		};

		audio_internal_mclk1_active: audio_internal_mclk1_active {
			mux {
				pins = "gpio97";
				function = "mi2s_mclk0";
			};

			config {
				pins = "gpio97";
				drive-strength = <8>;   /* 8 mA */
				bias-disable;           /* NO PULL */
				output-high;
			};
		};
	};
};
